# N575F145_v1 register map
File version: 1.0
Registers are 32-bit, read-write, reset 0x0 unless marked. A register's access mark holds for its fields unless they carry their own. Offsets are from the block's base; [hi:lo] are bit positions.

## PDMA_GCR — PDMA Register Map
Base 0x50008F00
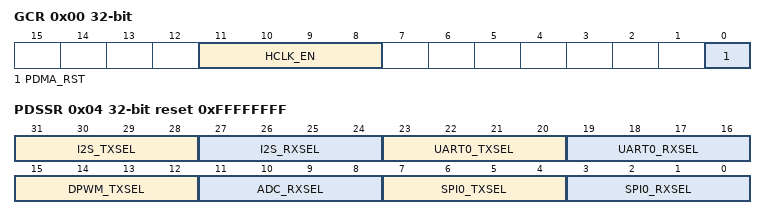
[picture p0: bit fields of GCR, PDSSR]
0x00 GCR — PDMA Global Control Register
  [11:8] HCLK_EN — PDMA Controller Channel Clock Enable Control. To enable clock for channel n HCLK_EN[n] must be set. HCLK_EN[n] = 1: Enable Channel n clock. HCLK_EN[n] = 0: Disable Channel n clock
  [0] PDMA_RST — PDMA Software Reset. Note: This bit can reset all channels (global reset).
    0=Writing 0 to this bit has no effect; 1=Writing 1 to this bit will reset the internal state machine and pointers. The contents of control register will not be cleared. This bit will auto clear after several clock cycles
0x04 PDSSR reset 0xFFFFFFFF — PDMA Service Selection Control Register
  [31:28] I2S_TXSEL — PDMA I2S Transmit Selection. This field defines which PDMA channel is connected to I2S peripheral transmit (PDMA destination) request.
  [27:24] I2S_RXSEL — PDMA I2S Receive Selection. This field defines which PDMA channel is connected to I2S peripheral receive (PDMA source) request.
  [23:20] UART0_TXSEL — PDMA UART0 Transmit Selection. This field defines which PDMA channel is connected to UART0 peripheral transmit (PDMA destination) request.
  [19:16] UART0_RXSEL — PDMA UART0 Receive Selection. This field defines which PDMA channel is connected to UART0 peripheral receive (PDMA source) request.
  [15:12] DPWM_TXSEL — PDMA DPWM Transmit Selection. This field defines which PDMA channel is connected to DPWM peripheral transmit (PDMA destination) request.
  [11:8] ADC_RXSEL — PDMA ADC Receive Selection. This field defines which PDMA channel is connected to ADC peripheral receive (PDMA source) request.
  [7:4] SPI0_TXSEL — PDMA SPI0 Transmit Selection. This field defines which PDMA channel is connected to SPI0 peripheral transmit (PDMA destination) request.
  [3:0] SPI0_RXSEL — PDMA SPI0 Receive Selection. This field defines which PDMA channel is connected to SPI0 peripheral receive (PDMA source) request.
0x0C GCRISR ro — PDMA Global Interrupt Status Register
  [3:0] GCRISR — Interrupt Pin Status (Read Only). GCRISR[n] is the interrupt status of PDMA channel n.

## FMC — FMC Register Map
Base 0x5000C000
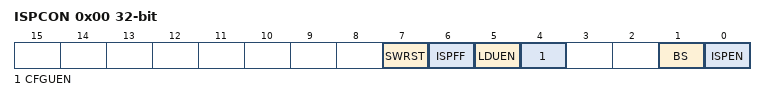
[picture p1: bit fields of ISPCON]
0x00 ISPCON — ISP Control Register
  [7] SWRST — Software Reset. Writing 1 to this bit will initiate a software reset. It is cleared by hardware after reset.
  [6] ISPFF — ISP Fail Flag. This bit is set by hardware when a triggered ISP meets any of the following conditions: (1) APROM writes to itself. (2) LDROM writes to itself. (3) Destination address is illegal, such as over an available range. Write 1 to clear.
  [5] LDUEN — LDROM Update Enable. LDROM update enable bit.
    0=LDROM cannot be updated; 1=LDROM can be updated when the MCU runs in APROM
  [4] CFGUEN — CONFIG Update Enable. When enabled, ISP functions can access the CONFIG address space and modify device configuration area.
    0=Disable; 1=Enable
  [1] BS — Boot Select. Modify this bit to select which ROM next boot is to occur. This bit also functions as MCU boot status flag, which can be used to check where MCU booted from. This bit is initialized after power-on reset with the inverse of CBS in Config0; It is not reset for any other reset event.
    0=APROM; 1=LDROM
  [0] ISPEN — ISP Enable
    0=Disable ISP function; 1=Enable ISP function
0x04 ISPADR — ISP Address Register
  [31:0] ISPADR — ISP Address Register. This is the memory address register that a subsequent ISP command will access. ISP operation are carried out on 32bit words only, consequently ISPARD[1:0] must be 00b for correct ISP operation.
0x08 ISPDAT — ISP Data Register
  [31:0] ISPDAT — ISP Data Register. Write data to this register before an ISP program operation. Read data from this register after an ISP read operation
0x0C ISPCMD — ISP Command Register
  [5:0] ISPCMD — ISP Command. Operation Mode : ISPCMD. Standby : 0x3X. Read : 0x00. Program : 0x21. Page Erase : 0x22. Read CID : 0x0B. Read DID : 0x0C
0x10 ISPTRG — ISP Trigger Control Register
  [0] ISPGO — ISP Start Trigger. Write 1 to start ISP operation. This will be cleared to 0 by hardware automatically when ISP operation is finished. After triggering an ISP function M0 instruction pipeline should be flushed with a ISB instruction to guarantee data integrity. This is a protected register, user must first follow the unlock sequence (see Protected Register Lock Key Register (REGLOCK)) to gain access.
    0=ISP operation is finished; 1=ISP is on going
0x14 DFBADR ro reset not defined — Data Flash Base Address
  [31:0] DFBA — Data Flash Base Address. This register reports the data flash starting address. It is a read only register. Data flash size is defined by user configuration, register content is loaded from Config1 when chip is reset.
